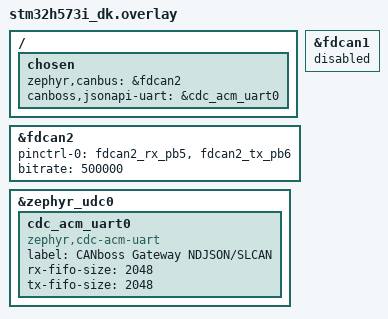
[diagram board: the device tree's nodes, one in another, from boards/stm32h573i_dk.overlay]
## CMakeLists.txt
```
# CANboss-Gateway: NDJSON-Interface fuer Webapps (lib/host_io) ueber
# eine UART (native_sim: PTY/stdio, stm32h573i_dk: USB-CDC-ACM am
# USB-Stecker des Boards; ST-Link-VCP siehe overlays/stlink_vcp.*).
#
#   west build -b native_sim/native/64 CANboss/apps/gateway -d build-gw
#   west build -b stm32h573i_dk       CANboss/apps/gateway -d build-gw-h573

cmake_minimum_required(VERSION 3.20.0)
find_package(Zephyr REQUIRED HINTS $ENV{ZEPHYR_BASE})
project(canboss_gateway LANGUAGES C)

set(REPO_ROOT ${CMAKE_CURRENT_SOURCE_DIR}/../..)
set(CANOPEN_DIR ${REPO_ROOT}/modules/CANopenNode)
set(CBLIB ${REPO_ROOT}/lib)

target_sources(app PRIVATE
    src/main.c
    # NDJSON-Dispatcher + SLCAN-Bruecke + RAM-Firmware-Slots
    ${CBLIB}/host_io/ndjson.c
    ${CBLIB}/host_io/ndjson_parse.c
    ${CBLIB}/host_io/slcan.c
    ${CBLIB}/host_io/ndjson_fw_ram.c
    # gemeinsame CANopen-Schicht
    ${CBLIB}/canopen/can_if.c
    ${CBLIB}/canopen/can_zephyr.c
    ${CBLIB}/canopen/osal_zephyr.c
    ${CBLIB}/canopen/co_node.c
    ${CBLIB}/canopen/port/CO_driver.c
    # CANopenNode-Stack inkl. Gateway-ASCII (CiA 309-3); Konfiguration
    # via CO_DRIVER_CUSTOM -> src/CO_driver_custom.h
    ${CANOPEN_DIR}/CANopen.c
    ${CANOPEN_DIR}/301/CO_ODinterface.c
    ${CANOPEN_DIR}/301/CO_NMT_Heartbeat.c
    ${CANOPEN_DIR}/301/CO_HBconsumer.c
    ${CANOPEN_DIR}/301/CO_Emergency.c
    ${CANOPEN_DIR}/301/CO_SDOserver.c
    ${CANOPEN_DIR}/301/CO_SDOclient.c
    ${CANOPEN_DIR}/301/CO_PDO.c
    ${CANOPEN_DIR}/301/CO_SYNC.c
    ${CANOPEN_DIR}/301/CO_TIME.c
    ${CANOPEN_DIR}/301/CO_fifo.c
    ${CANOPEN_DIR}/301/crc16-ccitt.c
    ${CANOPEN_DIR}/309/CO_gateway_ascii.c
)

# USB-Device (CDC-ACM) als NDJSON-Transport, z.B. stm32h573i_dk;
# lib/usbc: Dead-Battery-Rd + TCPP03-Bring-up fuer CN17 (H573I-DK)
target_sources_ifdef(CONFIG_CANBOSS_GW_USB app PRIVATE
    src/usb_cdc.c
    ${CBLIB}/usbc/usbc_h573_dk.c
)

target_include_directories(app PRIVATE
    src
    ${CBLIB}/host_io
    ${CBLIB}/usbc
    ${CBLIB}/canopen
    ${CBLIB}/canopen/port
    ${CANOPEN_DIR}
)

# Master-OD (canboss_master.eds; eingecheckte generierte Dateien)
include(${CBLIB}/od/od_codegen.cmake)
canboss_od_add(canboss_master)

target_compile_definitions(app PRIVATE
    CO_DRIVER_CUSTOM
    CB_FW_RAM_SLOTS=${CONFIG_CANBOSS_GW_FW_SLOTS}
    CB_FW_RAM_SLOT_SIZE=${CONFIG_CANBOSS_GW_FW_SLOT_SIZE}
)

# Berry-REPL im JSON-Interface (gemeinsame Schicht lib/berry_od;
# definiert CANBOSS_BERRY fuer die #ifdef-Gates in src/main.c)
if(CONFIG_CANBOSS_GW_BERRY)
    include(${CBLIB}/berry_od/berry.cmake)
endif()
```

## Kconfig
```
# SPDX-License-Identifier: Apache-2.0

menu "CANboss Gateway (NDJSON fuer Webapps)"

config CANBOSS_GW_NODE_ID
	int "Eigene CANopen-Node-ID"
	range 1 127
	default 126
	help
	  Default 126, damit das Gateway neben einem Monitor/Panel
	  (Node 127, canboss_master-Default) auf demselben Bus laufen kann.

config CANBOSS_GW_FW_SLOTS
	int "Firmware-Slots im RAM"
	range 1 4
	default 1

config CANBOSS_GW_FW_SLOT_SIZE
	int "Groesse je Firmware-Slot in Bytes"
	default 65536
	help
	  RAM-Backend (lib/host_io/ndjson_fw_ram.c) - nach Reset leer.
	  STM32H573 hat 640 KiB SRAM; native_sim ist unkritisch.

config CANBOSS_GW_BERRY
	bool "Berry-REPL im JSON-Interface ({\"repl\": ...})"
	default y
	help
	  Berry-VM mit den od_*-Bindings (lib/berry_od) einbauen; Webapps
	  koennen dann Berry-Code per {"repl": "od_read(16,0x1017,0)"}
	  ausfuehren. Kostet Flash/RAM und braucht Python (Berry-coc).

config CANBOSS_GW_CANOPEN
	bool "CANopen-Stack starten"
	default y
	help
	  Zum Eingrenzen von Problemen abschaltbar (z.B. USB-Bisect am
	  H573I-DK, overlays/nocanopen.conf): ohne CANopen laufen ping/
	  info/fw-Upload weiter, gtwa und SLCAN melden Fehler.

config CANBOSS_GW_USB
	bool "NDJSON ueber USB-CDC-ACM (statt ST-Link-VCP)"
	depends on USB_DEVICE_STACK_NEXT
	default y
	help
	  Auf Targets mit USB-Device-Controller (STM32H573I-DK: USB_DRD_FS
	  an PA11/PA12, Board-Label zephyr_udc0) laeuft der NDJSON-Strom
	  ueber eine CDC-ACM-Instanz am USB-Stecker des Boards. Der Browser
	  sieht sie als seriellen Port und erreicht sie per WebSerial - ohne
	  ST-Link, ohne Treiberinstallation.

	  Die Instanz und das chosen "canboss,jsonapi-uart" kommen aus
	  boards/stm32h573i_dk.overlay; zurueck auf die ST-Link-VCP geht es
	  mit overlays/stlink_vcp.overlay + overlays/stlink_vcp.conf.

if CANBOSS_GW_USB

config CANBOSS_GW_USB_VID
	hex "USB Vendor ID"
	default 0x0483
	help
	  STMicroelectronics (0x0483), damit WebSerial-Filter wie in LSM6
	  ({ usbVendorId: 0x0483 }) den User-USB-Port finden. Die
	  ST-LINK-VCP hat dieselbe VID (PID 0x374e) — im Picker den
	  Eintrag mit Produktstring "CANboss Gateway …" nehmen, nicht
	  den ST-LINK. lsusb ohne -v kommt aus usb.ids zum VID/PID-Paar.

config CANBOSS_GW_USB_PID
	hex "USB Product ID"
	default 0x5740
	help
	  STM32 Virtual COM Port (STs CDC-ACM-PID). Nicht 0x374e, das
	  ist die ST-LINK-VCP. usbdemo bleibt bei 1209:0001.

config CANBOSS_GW_USB_MANUFACTURER
	string "USB-Herstellerstring"
	default "Protronic GmbH"

config CANBOSS_GW_USB_PRODUCT
	string "USB-Produktstring"
	default "CANboss Gateway SLCAN"
	help
	  iProduct: WebSerial-Dialog, lsusb -v, udev ATTRS{product} und
	  /dev/serial/by-id/usb-Protronic_GmbH_CANboss_Gateway_SLCAN_*.
	  slcand sollte diesen by-id-Pfad nehmen, nicht /dev/ttyACM0
	  (das ist am H573I-DK die ST-LINK-VCP).

config CANBOSS_GW_USB_MAX_POWER
	int "bMaxPower in 2-mA-Schritten"
	range 0 250
	default 125
	help
	  125 = 250 mA. Das Gateway meldet sich bus-powered, damit die
	  Angabe unabhaengig davon stimmt, ob das DK ueber ST-Link oder
	  ueber den USB-FS-Stecker versorgt wird.

endif # CANBOSS_GW_USB

endmenu

source "Kconfig.zephyr"
```

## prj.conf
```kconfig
# CANboss-Gateway: CANopen + NDJSON ueber UART

CONFIG_CAN=y
CONFIG_SERIAL=y
CONFIG_RING_BUFFER=y

# Berry-Compiler ({"repl": ...}) parst rekursiv im Main-Thread
CONFIG_MAIN_STACK_SIZE=16384

# Der NDJSON-Strom teilt sich die UART nicht mit Konsole/Logs:
# Boards leiten die Konsole um oder schalten sie ab (boards/*.conf).
CONFIG_BOOT_BANNER=n
```

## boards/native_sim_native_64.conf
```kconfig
# NDJSON auf stdin/stdout des Host-Prozesses:
#   ./build/zephyr/zephyr.exe            (interaktiv/socat)
#   echo '{"ping":1}' | ./build/zephyr/zephyr.exe
CONFIG_SERIAL=y
CONFIG_UART_NATIVE_PTY=y
CONFIG_UART_NATIVE_PTY_0_ON_STDINOUT=y

# stdout gehoert dem NDJSON-Strom: Konsole/Logs aus
CONFIG_UART_CONSOLE=n
CONFIG_LOG=n
```

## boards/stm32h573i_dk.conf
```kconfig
# NDJSON laeuft ueber USB-CDC-ACM am USB-Stecker des Boards
# (boards/stm32h573i_dk.overlay: chosen canboss,jsonapi-uart).
CONFIG_USB_DEVICE_STACK_NEXT=y
CONFIG_USBD_CDC_ACM_CLASS=y
CONFIG_UART_LINE_CTRL=y

# Seriennummer aus der STM32-UID: der Browser kann so mehrere Gateways
# am selben Rechner auseinanderhalten.
CONFIG_HWINFO=y

# TCPP03-M20 auf CN17 (I2C4 @ 0x34, Enable PG0) - ohne den Chip im
# NORMAL-Modus enumeriert der Host das USB-FS-Device nicht.
CONFIG_I2C=y
CONFIG_I2C_SHELL=y

# Der UDC-Event-Thread des STM32-Treibers hat per Default nur 512 B
# Stack; laeuft er ueber, schiesst HW_STACK_PROTECTION nur diesen
# Thread ab und USB verstummt kommentarlos (Suspend kam noch, Resets
# vom Host kommen nie an). 1 KiB kostet nichts.
CONFIG_UDC_STM32_STACK_SIZE=1024

# CDC-ACM bekommt eine eigene Workqueue statt der System-Workqueue:
# der NDJSON-Transport darf nicht stehenbleiben, wenn irgendein anderes
# Work-Item (CAN, Sensorik, ...) die System-Queue blockiert.
CONFIG_USBD_CDC_ACM_WORKQUEUE=y
CONFIG_SYSTEM_WORKQUEUE_STACK_SIZE=2048

# Der NDJSON-Strom haengt jetzt am USB - die ST-Link-VCP ist die
# Zephyr-Konsole (Board-chosen zephyr,console = usart1): Boot-Banner,
# Statusmeldungen des Gateways (src/main.c, src/usb_cdc.c) und der
# USB-Enumerations-Fortschritt landen dort mit 115200 Baud.
# LOG_INF zusaetzlich per SEGGER RTT in die Debug-Session (probe-rs /
# Cortex-Debug RTT-Terminal). DROP, damit das Target ohne Debugger
# nicht an vollem RTT-Puffer haengt.
CONFIG_UART_CONSOLE=y
CONFIG_LOG=y
CONFIG_LOG_MODE_DEFERRED=y
CONFIG_USE_SEGGER_RTT=y
CONFIG_LOG_BACKEND_RTT=y
CONFIG_LOG_BACKEND_RTT_MODE_DROP=y
CONFIG_BOOT_BANNER=y

# Zephyr-Shell auf der Konsole (chosen zephyr,shell-uart = usart1):
# interaktives Monitoring beim Bring-up - "usbd device status",
# "can show fdcan@...", "device list", "kernel threads/uptime".
CONFIG_SHELL=y
CONFIG_DEVICE_SHELL=y
CONFIG_KERNEL_SHELL=y
CONFIG_CAN_SHELL=y
CONFIG_USBD_SHELL=y
# fuer "kernel threads"/"kernel stacks"
CONFIG_THREAD_MONITOR=y
CONFIG_THREAD_NAME=y

# USBD-Stack auf INF: meldet Enumeration/Konfiguration auf der Konsole.
# CDC-ACM bleibt aus - usbd_cdc_acm.c macht auf INF-Level einen
# LOG_HEXDUMP jedes empfangenen Pakets; mit LOG_MODE_MINIMAL landet der
# synchron auf der 115200-Baud-VCP und wuerde jeden fw-Upload
# ausbremsen.
CONFIG_USBD_CDC_ACM_LOG_LEVEL_OFF=y
CONFIG_USBD_LOG_LEVEL_INF=y
CONFIG_UDC_DRIVER_LOG_LEVEL_ERR=y

# Berry (malloc/strtod) wie bei apps/touch mit fester malloc-Arena:
# der Default -1 ("Heap = Rest-RAM ab _end") ist auf diesem Target
# nie erprobt, waehrend 57344 auf demselben Board seit langem laeuft.
CONFIG_COMMON_LIBC_MALLOC_ARENA_SIZE=57344

# Shell-Stack wie in apps/usbdemo (dort mit can/usbd-Kommandos erprobt)
CONFIG_SHELL_STACK_SIZE=4096

# 640 KiB SRAM: Default 1 Slot x 64 KiB (Kconfig CANBOSS_GW_FW_*)
```

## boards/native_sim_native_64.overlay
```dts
/*
 * native_sim: CAN ueber das Host-SocketCAN-Interface anbinden
 * (wie apps/monitor; vcan0 anlegen: sudo ip link add dev vcan0 type vcan
 *  && sudo ip link set vcan0 up).
 */

/ {
	chosen {
		zephyr,canbus = &can0;
	};
};

&can0 {
	status = "okay";
	host-interface = "vcan0";
};
```

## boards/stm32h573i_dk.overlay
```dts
/*
 * STM32H573I-DK: CAN ueber FDCAN2 am Arduino-Header (RX = D3 = PB5,
 * TX = D15 = PB6, Transceiver extern) - Pinout wie apps/touch.
 *
 * Der NDJSON-Strom laeuft ueber den USB-Stecker des Boards (USB_DRD_FS
 * an PA11/PA12, Board-Label zephyr_udc0) als CDC-ACM: WebSerial sieht
 * einen ganz normalen seriellen Port, ohne ST-Link und ohne Treiber.
 * Die ST-Link-VCP bleibt damit fuer Konsole/Logs frei.
 *
 * Zurueck auf die ST-Link-VCP (kein USB-Kabel am Board noetig):
 *   west build ... -- -DEXTRA_DTC_OVERLAY_FILE=overlays/stlink_vcp.overlay \
 *                     -DEXTRA_CONF_FILE=overlays/stlink_vcp.conf
 */

/ {
	chosen {
		zephyr,canbus = &fdcan2;
		canboss,jsonapi-uart = &cdc_acm_uart0;
	};
};

/*
 * Das Board-DTS aktiviert FDCAN1 standardmaessig auf PA11/PA12.
 * Dieselben Pins braucht USB_DRD_FS als D-/D+. Sobald CONFIG_CAN=y
 * ist, setzt der FDCAN1-Treiber die Pins beim Boot auf AF9 um und
 * trennt damit USB vom Stecker. Das Gateway nutzt FDCAN2 auf PB5/PB6,
 * daher muss FDCAN1 hier explizit aus sein.
 */
&fdcan1 {
	status = "disabled";
};

&fdcan2 {
	status = "okay";
	pinctrl-0 = <&fdcan2_rx_pb5 &fdcan2_tx_pb6>;
	pinctrl-names = "default";
	bitrate = <500000>;
};

/*
 * FIFOs grosszuegiger als der Binding-Default (1 KiB): eine
 * fw-data-Zeile bringt ~2.8 KiB Base64 mit, und der NDJSON-Poll-Thread
 * leert die UART nur alle 2 ms.
 */
&zephyr_udc0 {
	cdc_acm_uart0: cdc_acm_uart0 {
		compatible = "zephyr,cdc-acm-uart";
		label = "CANboss Gateway NDJSON/SLCAN";
		rx-fifo-size = <2048>;
		tx-fifo-size = <2048>;
	};
};
```

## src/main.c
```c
/**
 * CANboss-Gateway: NDJSON-Interface (lib/host_io) fuer Webapps.
 *
 * Transport ist eine UART, ausgewaehlt ueber das chosen
 * "canboss,jsonapi-uart" (Fallback: zephyr,console):
 *   - native_sim:     stdin/stdout des Prozesses (Test per Pipe/socat)
 *   - stm32h573i_dk:  USB-CDC-ACM am USB-Stecker des Boards, im Browser
 *                     direkt per WebSerial erreichbar (src/usb_cdc.c);
 *                     die ST-Link-VCP bleibt frei fuer Konsole/Logs.
 *                     Rueckfall auf die VCP: overlays/stlink_vcp.*
 *
 * CANopen laeuft mit dem canboss_master-OD (Default-Node 126) auf dem
 * chosen zephyr,canbus; das CANopenNode-Gateway (CiA 309-3) wird ueber
 * CNT_GTWA=1 aktiviert und von ndjson als {"gtwa": ...} angesprochen.
 */

#include <zephyr/kernel.h>
#include <zephyr/device.h>
#include <zephyr/devicetree.h>
#include <zephyr/drivers/uart.h>
#include <zephyr/logging/log.h>

/* Statusmeldungen auf der Zephyr-Konsole (stm32h573i_dk: ST-Link-VCP,
 * boards/stm32h573i_dk.conf). Auf native_sim ist CONFIG_LOG=n - dort
 * gehoert stdout dem NDJSON-Strom und LOG_* compiliert zu nichts. */
LOG_MODULE_REGISTER(canboss_gw, LOG_LEVEL_INF);

#include <stdio.h>
#include <string.h>

#include "co_node.h"
#include "canboss_master.h" /* nach co_node.h (CANopenNode-Typen) */
#include "ndjson.h"
#include "usb_cdc.h"

#ifdef CANBOSS_BERRY
#include "canboss_berry.h"
#endif

#if DT_HAS_CHOSEN(canboss_jsonapi_uart)
#define GW_UART_NODE DT_CHOSEN(canboss_jsonapi_uart)
#else
#define GW_UART_NODE DT_CHOSEN(zephyr_console)
#endif

static const struct device* const gw_uart = DEVICE_DT_GET(GW_UART_NODE);

static void
sink_write(void* user, const void* buf, size_t len) {
    const uint8_t* p = buf;

    (void)user;
    for (size_t i = 0; i < len; i++) {
        uart_poll_out(gw_uart, p[i]);
    }
}

#ifdef CANBOSS_BERRY
/* {"repl": ...}: canboss_berry_exec() im poll-Kontext; die
 * Berry-Ausgabe (be_writebuffer -> lib/berry_od/berry_port.c -> Senke)
 * geht an ndjson_repl_out und damit als {"repl":…} raus. */
static void
berry_sink(void* user, const char* buf, size_t len) {
    (void)user;
    ndjson_repl_out(buf, len);
}

static int
repl_exec(void* user, const char* code) {
    (void)user;
    return canboss_berry_exec(code);
}
#endif

int
main(void) {
    const cb_can_backend_t* backend = cb_can_backend_find("zephyr");

    if (!device_is_ready(gw_uart)) {
        return -1;
    }

    LOG_INF("CANboss-Gateway startet (Node-ID %d)", CONFIG_CANBOSS_GW_NODE_ID);

    /* USB-Device hochfahren, bevor CANopen startet: die Enumeration
     * laeuft dann parallel zur Bus-Initialisierung. Ohne
     * CONFIG_CANBOSS_GW_USB (native_sim, VCP-Variante) ein No-op. */
    int usb_err = canboss_usb_init();

    if (usb_err != 0) {
        LOG_ERR("USB-CDC-Init fehlgeschlagen (%d) - NDJSON-Transport tot", usb_err);
    }

    ndjson_sink_t sink = {.write = sink_write, .user = NULL};

    (void)ndjson_init(&sink, &ndjson_fw_ram);

#ifdef CANBOSS_BERRY
    canboss_berry_init(canboss_master);
    cb_berry_set_sink(berry_sink, NULL);
    ndjson_set_repl(repl_exec, NULL);
    LOG_INF("Berry-REPL bereit");
#endif

    /* OD-Konfiguration des Masters (muss den Stack ueberleben) */
    static CO_config_t cfg;

    memset(&cfg, 0, sizeof(cfg));
    canboss_master_INIT_CONFIG(cfg);
    cfg.CNT_GTWA = 1; /* Gateway-ASCII aktivieren (co_node/ndjson) */

    if (!IS_ENABLED(CONFIG_CANBOSS_GW_CANOPEN)) {
        LOG_WRN("CANopen deaktiviert (CONFIG_CANBOSS_GW_CANOPEN=n) - nur USB/NDJSON");
    } else if (cb_co_start(canboss_master, &cfg, backend, "zephyr,canbus", 0, CONFIG_CANBOSS_GW_NODE_ID) != 0) {
        char msg[192];
        int n = snprintf(msg, sizeof(msg), "{\"err\":\"CANopen offline: %s\"}\n", cb_co_error());

        if (n > 0) {
            sink_write(NULL, msg, (size_t)n);
        }
        LOG_ERR("CANopen offline: %s", cb_co_error());
        /* weiterlaufen: ping/info/fw-Upload gehen auch offline */
    } else {
        LOG_INF("CANopen laeuft (gtwa + SLCAN bereit)");
    }

    LOG_INF("NDJSON-Loop laeuft (Transport: %s)", gw_uart->name);

    for (;;) {
        unsigned char c;

        /* Webapp hat den Port gerade geoeffnet: eine Zeile abschliessen,
         * die noch im TX-Puffer stand (etwa die Offline-Meldung von
         * oben). Sonst setzt die Webapp auf einem Fragment auf und
         * verwirft die erste echte Antwort als Parse-Fehler. */
        if (canboss_usb_take_attach()) {
            sink_write(NULL, "\n", 1);
        }

        while (uart_poll_in(gw_uart, &c) == 0) {
            ndjson_input(&c, 1);
        }
        ndjson_poll();
        k_sleep(K_MSEC(2));
    }
    return 0;
}
```

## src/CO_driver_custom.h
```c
/**
 * CO_driver_custom.h - CANopenNode-Overrides der Gateway-App
 * (eingebunden von lib/canopen/port/CO_driver_target.h via
 * Compile-Definition CO_DRIVER_CUSTOM).
 *
 * - Gateway-ASCII (CiA 309-3) mit SDO-Client und NMT-Master-Kommandos;
 *   dafuer braucht die FIFO die ASCII-Kommando-/Datentyp-Funktionen.
 * - SDO-Client mit Block-Transfer (Firmware-Streaming, 0x1F50) inkl.
 *   der dafuer noetigen FIFO/CRC16-Flags.
 * - Groesserer GTWA-Kommandopuffer (Block-Downloads ueber das Gateway).
 */

#ifndef CO_DRIVER_CUSTOM_H_
#define CO_DRIVER_CUSTOM_H_

#define CO_CONFIG_NMT (CO_CONFIG_NMT_MASTER | CO_CONFIG_GLOBAL_FLAG_CALLBACK_PRE | CO_CONFIG_GLOBAL_FLAG_TIMERNEXT)

#define CO_CONFIG_GTW                                                                                                  \
    (CO_CONFIG_GTW_ASCII | CO_CONFIG_GTW_ASCII_SDO | CO_CONFIG_GTW_ASCII_NMT | CO_CONFIG_GTW_ASCII_ERROR_DESC          \
     | CO_CONFIG_GTW_ASCII_LOG | CO_CONFIG_GTW_ASCII_PRINT_HELP)
#define CO_CONFIG_GTWA_COMM_BUF_SIZE 1000
#define CO_CONFIG_GTWA_LOG_BUF_SIZE  256 /* Default nur unter CO_DOXYGEN */

/* CO_gateway_ascii.c nutzt das Makro ohne eigenen Default (nur unter
 * CO_DOXYGEN definiert) - ohne diese Zeile bricht der Build ab, sobald
 * GTW_ASCII_SDO und SDO_CLI_BLOCK zusammen an sind. 3 Durchlaeufe je
 * process() beschleunigen den Block-Download, solange die CAN-TX-Queue
 * des Treibers Platz hat. */
#define CO_CONFIG_GTW_BLOCK_DL_LOOP 3

#define CO_CONFIG_CRC16 (CO_CONFIG_CRC16_ENABLE)

#define CO_CONFIG_SDO_CLI (CO_CONFIG_SDO_CLI_ENABLE | CO_CONFIG_SDO_CLI_SEGMENTED | CO_CONFIG_SDO_CLI_BLOCK)

#define CO_CONFIG_FIFO                                                                                                 \
    (CO_CONFIG_FIFO_ENABLE | CO_CONFIG_FIFO_ALT_READ | CO_CONFIG_FIFO_CRC16_CCITT | CO_CONFIG_FIFO_ASCII_COMMANDS      \
     | CO_CONFIG_FIFO_ASCII_DATATYPES)

#endif /* CO_DRIVER_CUSTOM_H_ */
```

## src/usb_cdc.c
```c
/**
 * usb_cdc.c - USB-Device-Setup (CDC-ACM) fuer das NDJSON-Gateway,
 * siehe usb_cdc.h.
 *
 * Aufbau wie in Zephyrs USB-Device-Next-Beispielen: ein Kontext, eine
 * Full-Speed-Konfiguration, alle im Devicetree instanziierten Klassen
 * (hier genau die cdc_acm_uart0 aus boards/stm32h573i_dk.overlay).
 * Die Seriennummer kommt aus hwinfo (STM32-UID) - so unterscheidet der
 * Browser mehrere Gateways am selben Rechner.
 */

#include "usb_cdc.h"

#include <errno.h>

#include <zephyr/device.h>
#include <zephyr/drivers/uart.h>
#include <zephyr/kernel.h>
#include <zephyr/usb/usbd.h>

#include "usbc_h573_dk.h" /* Dead-Battery-Rd + TCPP03 (CN17) */

#include <zephyr/logging/log.h>
LOG_MODULE_REGISTER(canboss_usb, LOG_LEVEL_INF);

/* Die DFU-Mode-Instanz nie automatisch registrieren (wie in Zephyrs
 * Beispielen); das Gateway bringt ohnehin nur CDC-ACM mit. */
static const char* const class_blocklist[] = {
    "dfu_dfu",
    NULL,
};

USBD_DEVICE_DEFINE(gw_usbd, DEVICE_DT_GET(DT_NODELABEL(zephyr_udc0)), CONFIG_CANBOSS_GW_USB_VID,
                   CONFIG_CANBOSS_GW_USB_PID);

USBD_DESC_LANG_DEFINE(gw_lang);
USBD_DESC_MANUFACTURER_DEFINE(gw_mfr, CONFIG_CANBOSS_GW_USB_MANUFACTURER);
USBD_DESC_PRODUCT_DEFINE(gw_product, CONFIG_CANBOSS_GW_USB_PRODUCT);
USBD_DESC_SERIAL_NUMBER_DEFINE(gw_sn);
USBD_DESC_CONFIG_DEFINE(gw_fs_cfg_desc, "CANboss Gateway (NDJSON/SLCAN)");

/* Bus-powered gemeldet: das DK kann sowohl ueber ST-Link als auch ueber
 * den USB-FS-Stecker versorgt werden - die Angabe passt in beiden
 * Faellen, waehrend "self-powered" bei Busversorgung falsch waere. */
USBD_CONFIGURATION_DEFINE(gw_fs_config, 0, CONFIG_CANBOSS_GW_USB_MAX_POWER, &gw_fs_cfg_desc);

/* DTR-Flanke: der Host hat den Port geoeffnet (Webapp verbunden) */
static atomic_t attach_pending;

static void
usbd_msg_cb(struct usbd_context* const ctx, const struct usbd_msg* msg) {
    /* Enumerations-Fortschritt auf der Konsole (ST-Link-VCP):
     * reset -> configuration -> cdc_acm_line_coding usw. */
    LOG_INF("USBD: %s", usbd_msg_type_string(msg->type));

    if (usbd_can_detect_vbus(ctx)) {
        if (msg->type == USBD_MSG_VBUS_READY) {
            (void)usbd_enable(ctx);
        }
        if (msg->type == USBD_MSG_VBUS_REMOVED) {
            (void)usbd_disable(ctx);
        }
    }

    if (msg->type == USBD_MSG_CDC_ACM_CONTROL_LINE_STATE) {
        uint32_t dtr = 0U;

        (void)uart_line_ctrl_get(msg->dev, UART_LINE_CTRL_DTR, &dtr);
        if (dtr) {
            atomic_set(&attach_pending, 1);
        }
    }
}

int
canboss_usb_init(void) {
    int err;

    /* CN17-Vorarbeit (Rd-Status, TCPP03 -> NORMAL); Fehler nur loggen -
     * an einem USB-A-Host enumeriert das Device u.U. trotzdem. */
    (void)canboss_usbc_prepare();

    if (!device_is_ready(DEVICE_DT_GET(DT_NODELABEL(zephyr_udc0)))) {
        LOG_ERR("UDC-Controller nicht bereit");
        return -ENODEV;
    }

    err = usbd_add_descriptor(&gw_usbd, &gw_lang);
    if (err == 0) {
        err = usbd_add_descriptor(&gw_usbd, &gw_mfr);
    }
    if (err == 0) {
        err = usbd_add_descriptor(&gw_usbd, &gw_product);
    }
    if (err == 0) {
        err = usbd_add_descriptor(&gw_usbd, &gw_sn);
    }
    if (err) {
        LOG_ERR("Deskriptor abgelehnt (%d)", err);
        return err;
    }

    err = usbd_add_configuration(&gw_usbd, USBD_SPEED_FS, &gw_fs_config);
    if (err) {
        LOG_ERR("Full-Speed-Konfiguration abgelehnt (%d)", err);
        return err;
    }

    err = usbd_register_all_classes(&gw_usbd, USBD_SPEED_FS, 1, class_blocklist);
    if (err) {
        LOG_ERR("Klassen-Registrierung fehlgeschlagen (%d)", err);
        return err;
    }

    /* CDC-ACM besteht aus zwei Interfaces und bringt eine IAD mit:
     * Klassencode im Device-Deskriptor auf "Miscellaneous / Common
     * Class / IAD", damit Windows die Funktion korrekt zusammenfasst. */
    (void)usbd_device_set_code_triple(&gw_usbd, USBD_SPEED_FS, USB_BCC_MISCELLANEOUS, 0x02, 0x01);
    usbd_self_powered(&gw_usbd, false);

    err = usbd_msg_register_cb(&gw_usbd, usbd_msg_cb);
    if (err) {
        LOG_ERR("Message-Callback abgelehnt (%d)", err);
        return err;
    }

    err = usbd_init(&gw_usbd);
    if (err) {
        LOG_ERR("usbd_init fehlgeschlagen (%d)", err);
        return err;
    }

    /* Ohne VBUS-Erkennung (STM32-UDC) direkt einschalten; sonst
     * uebernimmt das der USBD_MSG_VBUS_READY-Pfad im Callback. */
    if (!usbd_can_detect_vbus(&gw_usbd)) {
        err = usbd_enable(&gw_usbd);
        if (err) {
            LOG_ERR("usbd_enable fehlgeschlagen (%d)", err);
            return err;
        }
    }

    LOG_INF("USB-Device aktiv (VID/PID %04x:%04x), warte auf Host", CONFIG_CANBOSS_GW_USB_VID,
            CONFIG_CANBOSS_GW_USB_PID);
    return 0;
}

bool
canboss_usb_take_attach(void) {
    return atomic_cas(&attach_pending, 1, 0);
}
```

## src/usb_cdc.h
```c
/**
 * usb_cdc.h - USB-Device (CDC-ACM) fuer das NDJSON-Gateway.
 *
 * Auf Targets mit USB-Device-Controller (STM32H573I-DK: USB_DRD_FS an
 * PA11/PA12, Board-Label zephyr_udc0) laeuft der NDJSON-Strom ueber
 * eine CDC-ACM-Instanz statt ueber die ST-Link-VCP-UART. Der Browser
 * sieht sie als ganz normalen seriellen Port (WebSerial), ohne
 * Treiber und ohne ST-Link im Spiel.
 *
 * Ohne CONFIG_CANBOSS_GW_USB sind alle Funktionen No-ops, damit
 * native_sim und der VCP-Pfad unveraendert bauen.
 */

#ifndef CB_GW_USB_CDC_H_
#define CB_GW_USB_CDC_H_

#include <stdbool.h>

#ifdef CONFIG_CANBOSS_GW_USB

/* USB-Device aufsetzen (Deskriptoren, CDC-ACM) und einschalten.
 * 0 = ok; danach dauert es je nach Host ~1 s bis zur Enumeration. */
int canboss_usb_init(void);

/* true genau einmal je DTR-Flanke: der Host (die Webapp) hat den Port
 * gerade geoeffnet. Aufrufer nutzt das, um eine angefangene Zeile
 * abzuschliessen, damit die Webapp nicht auf einem Fragment aufsetzt. */
bool canboss_usb_take_attach(void);

#else

static inline int
canboss_usb_init(void) {
    return 0;
}

static inline bool
canboss_usb_take_attach(void) {
    return false;
}

#endif /* CONFIG_CANBOSS_GW_USB */

#endif /* CB_GW_USB_CDC_H_ */
```
